AUTOSAR XML (schema 4-2-2)
package /AUTOSAR_Dem/SwComponentTypes
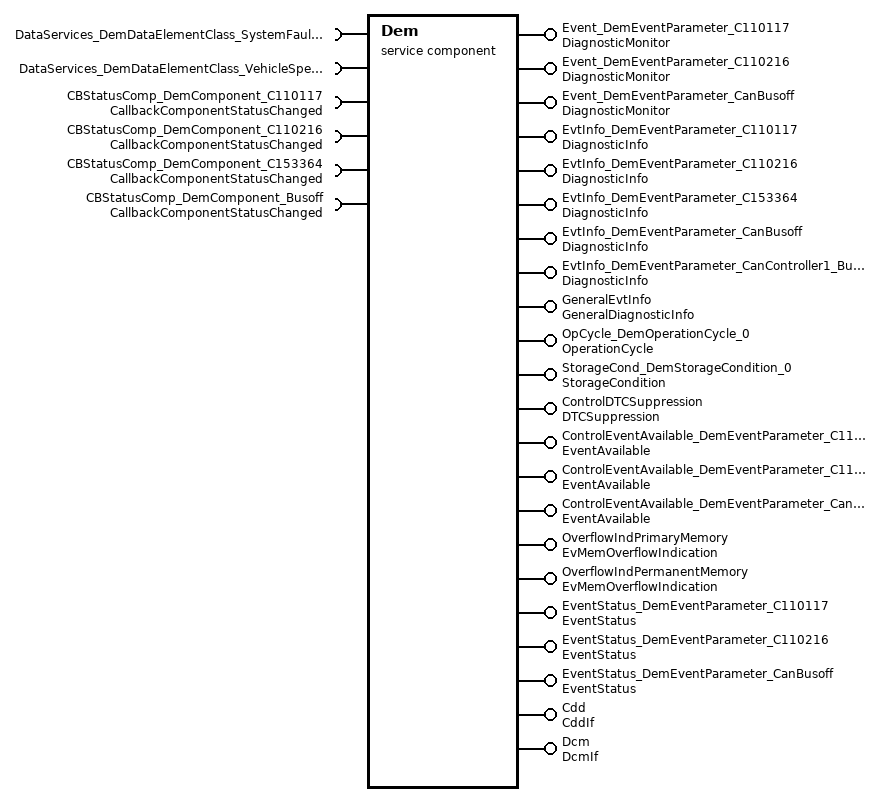
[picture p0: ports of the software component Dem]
  service sw component type Dem
    20 x provide port:
      Event_DemEventParameter_C110117: provided-interface=DiagnosticMonitor
      Event_DemEventParameter_C110216: provided-interface=DiagnosticMonitor
      Event_DemEventParameter_CanBusoff: provided-interface=DiagnosticMonitor
      EvtInfo_DemEventParameter_C110117: provided-interface=DiagnosticInfo
      EvtInfo_DemEventParameter_C110216: provided-interface=DiagnosticInfo
      EvtInfo_DemEventParameter_C153364: provided-interface=DiagnosticInfo
      EvtInfo_DemEventParameter_CanBusoff: provided-interface=DiagnosticInfo
      EvtInfo_DemEventParameter_CanController1_Busoff: provided-interface=DiagnosticInfo
      GeneralEvtInfo: provided-interface=GeneralDiagnosticInfo
      OpCycle_DemOperationCycle_0: provided-interface=OperationCycle
      StorageCond_DemStorageCondition_0: provided-interface=StorageCondition
      ControlDTCSuppression: provided-interface=DTCSuppression
      ControlEventAvailable_DemEventParameter_C110117: provided-interface=EventAvailable
      ControlEventAvailable_DemEventParameter_C110216: provided-interface=EventAvailable
      ControlEventAvailable_DemEventParameter_CanBusoff: provided-interface=EventAvailable
      OverflowIndPrimaryMemory: provided-interface=EvMemOverflowIndication
      OverflowIndPermanentMemory: provided-interface=EvMemOverflowIndication
      EventStatus_DemEventParameter_C110117: provided-interface=EventStatus
      EventStatus_DemEventParameter_C110216: provided-interface=EventStatus
      EventStatus_DemEventParameter_CanBusoff: provided-interface=EventStatus
    6 x require port:
      DataServices_DemDataElementClass_SystemFaultRank: required-interface=DataServices_DemDataElementClass_SystemFaultRank
      DataServices_DemDataElementClass_VehicleSpeed: required-interface=DataServices_DemDataElementClass_VehicleSpeed
      CBStatusComp_DemComponent_C110117: required-interface=CallbackComponentStatusChanged
      CBStatusComp_DemComponent_C110216: required-interface=CallbackComponentStatusChanged
      CBStatusComp_DemComponent_C153364: required-interface=CallbackComponentStatusChanged
      CBStatusComp_DemComponent_Busoff: required-interface=CallbackComponentStatusChanged
    provide port Cdd: provided-interface=CddIf
    provide port Dcm: provided-interface=DcmIf
    behavior IntBeh_Dem: included-data-type-set=data-type=[Dem_DTCFormatType, Dem_DTCOriginType, Dem_EventIdType, Dem_UdsStatusByteType, Dem_EventStatusType, Dem_IndicatorIdType, Dem_IndicatorStatusType, Dem_InitMonitorReasonType, Dem_MaxDataValueType, Dem_OperationCycleIdType, Dem_OperationCycleStateType, Dem_ReturnClearDTCType, Dem_DebouncingStateType, Dem_DebounceResetStatusType]
      94 x operation invoked event:
        Ev_SES_DemEventParameter_C110117: start-on-event=SetEventStatus, operation=Event_DemEventParameter_C110117.SetEventStatus
        Ev_RES_DemEventParameter_C110117: start-on-event=ResetEventStatus, operation=Event_DemEventParameter_C110117.ResetEventStatus
        Ev_CPFF_DemEventParameter_C110117: start-on-event=ClearPrestoredFreezeFrame, operation=Event_DemEventParameter_C110117.ClearPrestoredFreezeFrame
        Ev_PFF_DemEventParameter_C110117: start-on-event=PrestoreFreezeFrame, operation=Event_DemEventParameter_C110117.PrestoreFreezeFrame
        Ev_RDS_DemEventParameter_C110117: start-on-event=ResetEventDebounceStatus, operation=Event_DemEventParameter_C110117.ResetEventDebounceStatus
        Ev_SES_DemEventParameter_C110216: start-on-event=SetEventStatus, operation=Event_DemEventParameter_C110216.SetEventStatus
        Ev_RES_DemEventParameter_C110216: start-on-event=ResetEventStatus, operation=Event_DemEventParameter_C110216.ResetEventStatus
        Ev_CPFF_DemEventParameter_C110216: start-on-event=ClearPrestoredFreezeFrame, operation=Event_DemEventParameter_C110216.ClearPrestoredFreezeFrame
        Ev_PFF_DemEventParameter_C110216: start-on-event=PrestoreFreezeFrame, operation=Event_DemEventParameter_C110216.PrestoreFreezeFrame
        Ev_RDS_DemEventParameter_C110216: start-on-event=ResetEventDebounceStatus, operation=Event_DemEventParameter_C110216.ResetEventDebounceStatus
        Ev_SES_DemEventParameter_CanBusoff: start-on-event=SetEventStatus, operation=Event_DemEventParameter_CanBusoff.SetEventStatus
        Ev_RES_DemEventParameter_CanBusoff: start-on-event=ResetEventStatus, operation=Event_DemEventParameter_CanBusoff.ResetEventStatus
        Ev_CPFF_DemEventParameter_CanBusoff: start-on-event=ClearPrestoredFreezeFrame, operation=Event_DemEventParameter_CanBusoff.ClearPrestoredFreezeFrame
        Ev_PFF_DemEventParameter_CanBusoff: start-on-event=PrestoreFreezeFrame, operation=Event_DemEventParameter_CanBusoff.PrestoreFreezeFrame
        Ev_RDS_DemEventParameter_CanBusoff: start-on-event=ResetEventDebounceStatus, operation=Event_DemEventParameter_CanBusoff.ResetEventDebounceStatus
        Ev_GES_DemEventParameter_C110117: start-on-event=GetEventStatus, operation=EvtInfo_DemEventParameter_C110117.GetEventStatus
        Ev_GEF_DemEventParameter_C110117: start-on-event=GetEventFailed, operation=EvtInfo_DemEventParameter_C110117.GetEventFailed
        Ev_GET_DemEventParameter_C110117: start-on-event=GetEventTested, operation=EvtInfo_DemEventParameter_C110117.GetEventTested
        Ev_GDOE_DemEventParameter_C110117: start-on-event=GetDTCOfEvent, operation=EvtInfo_DemEventParameter_C110117.GetDTCOfEvent
        Ev_GETDOE_DemEventParameter_C110117: start-on-event=GetDebouncingOfEvent, operation=EvtInfo_DemEventParameter_C110117.GetDebouncingOfEvent
        Ev_GFDC_DemEventParameter_C110117: start-on-event=GetFaultDetectionCounter, operation=EvtInfo_DemEventParameter_C110117.GetFaultDetectionCounter
        Ev_GEED_DemEventParameter_C110117: start-on-event=GetEventExtendedDataRecord, operation=EvtInfo_DemEventParameter_C110117.GetEventExtendedDataRecord
        Ev_GEEDR_DemEventParameter_C110117: start-on-event=GetEventExtendedDataRecordEx, operation=EvtInfo_DemEventParameter_C110117.GetEventExtendedDataRecordEx
        Ev_GEFFD_DemEventParameter_C110117: start-on-event=GetEventFreezeFrameData, operation=EvtInfo_DemEventParameter_C110117.GetEventFreezeFrameData
        Ev_GEFFDE_DemEventParameter_C110117: start-on-event=GetEventFreezeFrameDataEx, operation=EvtInfo_DemEventParameter_C110117.GetEventFreezeFrameDataEx
        Ev_GES_DemEventParameter_C110216: start-on-event=GetEventStatus, operation=EvtInfo_DemEventParameter_C110216.GetEventStatus
        Ev_GEF_DemEventParameter_C110216: start-on-event=GetEventFailed, operation=EvtInfo_DemEventParameter_C110216.GetEventFailed
        Ev_GET_DemEventParameter_C110216: start-on-event=GetEventTested, operation=EvtInfo_DemEventParameter_C110216.GetEventTested
        Ev_GDOE_DemEventParameter_C110216: start-on-event=GetDTCOfEvent, operation=EvtInfo_DemEventParameter_C110216.GetDTCOfEvent
        Ev_GETDOE_DemEventParameter_C110216: start-on-event=GetDebouncingOfEvent, operation=EvtInfo_DemEventParameter_C110216.GetDebouncingOfEvent
        Ev_GFDC_DemEventParameter_C110216: start-on-event=GetFaultDetectionCounter, operation=EvtInfo_DemEventParameter_C110216.GetFaultDetectionCounter
        Ev_GEED_DemEventParameter_C110216: start-on-event=GetEventExtendedDataRecord, operation=EvtInfo_DemEventParameter_C110216.GetEventExtendedDataRecord
        Ev_GEEDR_DemEventParameter_C110216: start-on-event=GetEventExtendedDataRecordEx, operation=EvtInfo_DemEventParameter_C110216.GetEventExtendedDataRecordEx
        Ev_GEFFD_DemEventParameter_C110216: start-on-event=GetEventFreezeFrameData, operation=EvtInfo_DemEventParameter_C110216.GetEventFreezeFrameData
        Ev_GEFFDE_DemEventParameter_C110216: start-on-event=GetEventFreezeFrameDataEx, operation=EvtInfo_DemEventParameter_C110216.GetEventFreezeFrameDataEx
        Ev_GES_DemEventParameter_C153364: start-on-event=GetEventStatus, operation=EvtInfo_DemEventParameter_C153364.GetEventStatus
        Ev_GEF_DemEventParameter_C153364: start-on-event=GetEventFailed, operation=EvtInfo_DemEventParameter_C153364.GetEventFailed
        Ev_GET_DemEventParameter_C153364: start-on-event=GetEventTested, operation=EvtInfo_DemEventParameter_C153364.GetEventTested
        Ev_GDOE_DemEventParameter_C153364: start-on-event=GetDTCOfEvent, operation=EvtInfo_DemEventParameter_C153364.GetDTCOfEvent
        Ev_GETDOE_DemEventParameter_C153364: start-on-event=GetDebouncingOfEvent, operation=EvtInfo_DemEventParameter_C153364.GetDebouncingOfEvent
        Ev_GFDC_DemEventParameter_C153364: start-on-event=GetFaultDetectionCounter, operation=EvtInfo_DemEventParameter_C153364.GetFaultDetectionCounter
        Ev_GEED_DemEventParameter_C153364: start-on-event=GetEventExtendedDataRecord, operation=EvtInfo_DemEventParameter_C153364.GetEventExtendedDataRecord
        Ev_GEEDR_DemEventParameter_C153364: start-on-event=GetEventExtendedDataRecordEx, operation=EvtInfo_DemEventParameter_C153364.GetEventExtendedDataRecordEx
        Ev_GEFFD_DemEventParameter_C153364: start-on-event=GetEventFreezeFrameData, operation=EvtInfo_DemEventParameter_C153364.GetEventFreezeFrameData
        Ev_GEFFDE_DemEventParameter_C153364: start-on-event=GetEventFreezeFrameDataEx, operation=EvtInfo_DemEventParameter_C153364.GetEventFreezeFrameDataEx
        Ev_GES_DemEventParameter_CanBusoff: start-on-event=GetEventStatus, operation=EvtInfo_DemEventParameter_CanBusoff.GetEventStatus
        Ev_GEF_DemEventParameter_CanBusoff: start-on-event=GetEventFailed, operation=EvtInfo_DemEventParameter_CanBusoff.GetEventFailed
        Ev_GET_DemEventParameter_CanBusoff: start-on-event=GetEventTested, operation=EvtInfo_DemEventParameter_CanBusoff.GetEventTested
        Ev_GDOE_DemEventParameter_CanBusoff: start-on-event=GetDTCOfEvent, operation=EvtInfo_DemEventParameter_CanBusoff.GetDTCOfEvent
        Ev_GETDOE_DemEventParameter_CanBusoff: start-on-event=GetDebouncingOfEvent, operation=EvtInfo_DemEventParameter_CanBusoff.GetDebouncingOfEvent
        Ev_GFDC_DemEventParameter_CanBusoff: start-on-event=GetFaultDetectionCounter, operation=EvtInfo_DemEventParameter_CanBusoff.GetFaultDetectionCounter
        Ev_GEED_DemEventParameter_CanBusoff: start-on-event=GetEventExtendedDataRecord, operation=EvtInfo_DemEventParameter_CanBusoff.GetEventExtendedDataRecord
        Ev_GEEDR_DemEventParameter_CanBusoff: start-on-event=GetEventExtendedDataRecordEx, operation=EvtInfo_DemEventParameter_CanBusoff.GetEventExtendedDataRecordEx
        Ev_GEFFD_DemEventParameter_CanBusoff: start-on-event=GetEventFreezeFrameData, operation=EvtInfo_DemEventParameter_CanBusoff.GetEventFreezeFrameData
        Ev_GEFFDE_DemEventParameter_CanBusoff: start-on-event=GetEventFreezeFrameDataEx, operation=EvtInfo_DemEventParameter_CanBusoff.GetEventFreezeFrameDataEx
        Ev_GES_DemEventParameter_CanController1_Busoff: start-on-event=GetEventStatus, operation=EvtInfo_DemEventParameter_CanController1_Busoff.GetEventStatus
        Ev_GEF_DemEventParameter_CanController1_Busoff: start-on-event=GetEventFailed, operation=EvtInfo_DemEventParameter_CanController1_Busoff.GetEventFailed
        Ev_GET_DemEventParameter_CanController1_Busoff: start-on-event=GetEventTested, operation=EvtInfo_DemEventParameter_CanController1_Busoff.GetEventTested
        Ev_GDOE_DemEventParameter_CanController1_Busoff: start-on-event=GetDTCOfEvent, operation=EvtInfo_DemEventParameter_CanController1_Busoff.GetDTCOfEvent
        Ev_GETDOE_DemEventParameter_CanController1_Busoff: start-on-event=GetDebouncingOfEvent, operation=EvtInfo_DemEventParameter_CanController1_Busoff.GetDebouncingOfEvent
        Ev_GFDC_DemEventParameter_CanController1_Busoff: start-on-event=GetFaultDetectionCounter, operation=EvtInfo_DemEventParameter_CanController1_Busoff.GetFaultDetectionCounter
        Ev_GEED_DemEventParameter_CanController1_Busoff: start-on-event=GetEventExtendedDataRecord, operation=EvtInfo_DemEventParameter_CanController1_Busoff.GetEventExtendedDataRecord
        Ev_GEEDR_DemEventParameter_CanController1_Busoff: start-on-event=GetEventExtendedDataRecordEx, operation=EvtInfo_DemEventParameter_CanController1_Busoff.GetEventExtendedDataRecordEx
        Ev_GEFFD_DemEventParameter_CanController1_Busoff: start-on-event=GetEventFreezeFrameData, operation=EvtInfo_DemEventParameter_CanController1_Busoff.GetEventFreezeFrameData
        Ev_GEFFDE_DemEventParameter_CanController1_Busoff: start-on-event=GetEventFreezeFrameDataEx, operation=EvtInfo_DemEventParameter_CanController1_Busoff.GetEventFreezeFrameDataEx
        GDI_GDOE_GetDebouncingOfEvent: start-on-event=GetDebouncingOfEvent_GeneralEvtInfo, operation=GeneralEvtInfo.GetDebouncingOfEvent
        GDI_GES_GetEventStatus: start-on-event=Dem_GetEventStatus_GeneralEvtInfo, operation=GeneralEvtInfo.GetEventStatus
        GDI_GEF_GetEventFailed: start-on-event=Dem_GetEventFailed_GeneralEvtInfo, operation=GeneralEvtInfo.GetEventFailed
        GDI_GET_GetEventTested: start-on-event=Dem_GetEventTested_GeneralEvtInfo, operation=GeneralEvtInfo.GetEventTested
        GDI_GDE_GetDTCOfEvent: start-on-event=Dem_GetDTCOfEvent_GeneralEvtInfo, operation=GeneralEvtInfo.GetDTCOfEvent
        GDI_GFDC_GetFaultDetectionCounter: start-on-event=Dem_GetFaultDetectionCounter_GeneralEvtInfo, operation=GeneralEvtInfo.GetFaultDetectionCounter
        GDI_GEED_GetEventExtendedDataRecord: start-on-event=Dem_GetEventExtendedDataRecord_GeneralEvtInfo, operation=GeneralEvtInfo.GetEventExtendedDataRecord
        GDI_GEFFD_GetEventFreezeFrameData: start-on-event=Dem_GetEventFreezeFrameData_GeneralEvtInfo, operation=GeneralEvtInfo.GetEventFreezeFrameData
        GDI_GEED_GetEventExtendedDataRecordEx: start-on-event=Dem_GetEventExtendedDataRecordEx_GeneralEvtInfo, operation=GeneralEvtInfo.GetEventExtendedDataRecordEx
        GDI_GEFFD_GetEventFreezeFrameDataEx: start-on-event=Dem_GetEventFreezeFrameDataEx_GeneralEvtInfo, operation=GeneralEvtInfo.GetEventFreezeFrameDataEx
        OpCycle_OCS_DemOperationCycle_0: start-on-event=SetOperationCycleState, operation=OpCycle_DemOperationCycle_0.SetOperationCycleState
        OpCycle_GOCS_DemOperationCycle_0: start-on-event=GetOperationCycleState, operation=OpCycle_DemOperationCycle_0.GetOperationCycleState
        OpCycle_GCQ_DemOperationCycle_0: start-on-event=GetCycleQualified, operation=OpCycle_DemOperationCycle_0.GetCycleQualified
        OpCycle_SCQ_DemOperationCycle_0: start-on-event=SetCycleQualified, operation=OpCycle_DemOperationCycle_0.SetCycleQualified
        StorageCond_SSC_DemStorageCondition_0: start-on-event=SetStorageCondition, operation=StorageCond_DemStorageCondition_0.SetStorageCondition
        StorageCond_GSC_DemStorageCondition_0: start-on-event=GetStorageCondition, operation=StorageCond_DemStorageCondition_0.GetStorageCondition
        ControlDTCSuppression: start-on-event=SetDTCSuppression, operation=ControlDTCSuppression.SetDTCSuppression
        EvMemOverflow_GNOEE_OverflowIndPrimaryMemory: start-on-event=GetNumberOfEventMemoryEntries, operation=OverflowIndPrimaryMemory.GetNumberOfEventMemoryEntries
        EvMemOverflow_GEMO_OverflowIndPrimaryMemory: start-on-event=GetEventMemoryOverflow, operation=OverflowIndPrimaryMemory.GetEventMemoryOverflow
        EvMemOverflow_GEMO_OverflowIndPermanentMemory: start-on-event=GetEventMemoryOverflow, operation=OverflowIndPermanentMemory.GetEventMemoryOverflow
        EvMemOverflow_GNOEE_OverflowIndPermanentMemory: start-on-event=GetNumberOfEventMemoryEntries, operation=OverflowIndPermanentMemory.GetNumberOfEventMemoryEntries
        Ev_SetWIRStatus_DemEventParameter_C110117: start-on-event=SetWIRStatus, operation=EventStatus_DemEventParameter_C110117.SetWIRStatus
        Ev_SetWIRStatus_DemEventParameter_C110216: start-on-event=SetWIRStatus, operation=EventStatus_DemEventParameter_C110216.SetWIRStatus
        Ev_SetWIRStatus_DemEventParameter_CanBusoff: start-on-event=SetWIRStatus, operation=EventStatus_DemEventParameter_CanBusoff.SetWIRStatus
        Cdd: start-on-event=ClearDTC, operation=Cdd.ClearDTC
        Dcm: start-on-event=ClearDTC, operation=Dcm.ClearDTC
        EventAvailable_SetEventAvailable_DemEventParameter_C110117: start-on-event=SetEventAvailable, operation=ControlEventAvailable_DemEventParameter_C110117.SetEventAvailable
        EventAvailable_SetEventAvailable_DemEventParameter_C110216: start-on-event=SetEventAvailable, operation=ControlEventAvailable_DemEventParameter_C110216.SetEventAvailable
        EventAvailable_SetEventAvailable_DemEventParameter_CanBusoff: start-on-event=SetEventAvailable, operation=ControlEventAvailable_DemEventParameter_CanBusoff.SetEventAvailable
      port-api-options:
        {enable-take-address=true, indirect-api=false, port-defined-argument-value{value=EvtInfo_DemEventParameter_C110117:1, value-type=Dem_EventIdType}, port=EvtInfo_DemEventParameter_C110117}
        {enable-take-address=true, indirect-api=false, port-defined-argument-value{value=EvtInfo_DemEventParameter_C110216:2, value-type=Dem_EventIdType}, port=EvtInfo_DemEventParameter_C110216}
        {enable-take-address=true, indirect-api=false, port-defined-argument-value{value=EvtInfo_DemEventParameter_C153364:3, value-type=Dem_EventIdType}, port=EvtInfo_DemEventParameter_C153364}
        {enable-take-address=true, indirect-api=false, port-defined-argument-value{value=EvtInfo_DemEventParameter_CanBusoff:4, value-type=Dem_EventIdType}, port=EvtInfo_DemEventParameter_CanBusoff}
        {enable-take-address=true, indirect-api=false, port-defined-argument-value{value=EvtInfo_DemEventParameter_CanController1_Busoff:5, value-type=Dem_EventIdType}, port=EvtInfo_DemEventParameter_CanController1_Busoff}
        {enable-take-address=true, indirect-api=false, port-defined-argument-value{value=Event_DemEventParameter_C110117:1, value-type=Dem_EventIdType}, port=Event_DemEventParameter_C110117}
        {enable-take-address=true, indirect-api=false, port-defined-argument-value{value=EventStatus_DemEventParameter_C110117:1, value-type=Dem_EventIdType}, port=EventStatus_DemEventParameter_C110117}
        {enable-take-address=true, indirect-api=false, port-defined-argument-value{value=Event_DemEventParameter_C110216:2, value-type=Dem_EventIdType}, port=Event_DemEventParameter_C110216}
        {enable-take-address=true, indirect-api=false, port-defined-argument-value{value=EventStatus_DemEventParameter_C110216:2, value-type=Dem_EventIdType}, port=EventStatus_DemEventParameter_C110216}
        {enable-take-address=true, indirect-api=false, port-defined-argument-value{value=Event_DemEventParameter_CanBusoff:4, value-type=Dem_EventIdType}, port=Event_DemEventParameter_CanBusoff}
        {enable-take-address=true, indirect-api=false, port-defined-argument-value{value=EventStatus_DemEventParameter_CanBusoff:4, value-type=Dem_EventIdType}, port=EventStatus_DemEventParameter_CanBusoff}
        {enable-take-address=true, indirect-api=false, port-defined-argument-value{value=OpCycle_DemOperationCycle_0:0, value-type=Dem_OperationCycleIdType}, port=OpCycle_DemOperationCycle_0}
        {enable-take-address=true, indirect-api=false, port-defined-argument-value{value=StorageCond_DemStorageCondition_0:0, value-type=uint8}, port=StorageCond_DemStorageCondition_0}
        enable-take-address=true, indirect-api=false, port=ControlDTCSuppression
        enable-take-address=true, indirect-api=false, port=Cdd
        enable-take-address=true, indirect-api=false, port=Dcm
        {enable-take-address=true, indirect-api=false, port-defined-argument-value{value=OverflowIndPrimaryMemory:1, value-type=Dem_DTCOriginType}, port=OverflowIndPrimaryMemory}
        {enable-take-address=true, indirect-api=false, port-defined-argument-value{value=OverflowIndPermanentMemory:3, value-type=Dem_DTCOriginType}, port=OverflowIndPermanentMemory}
        enable-take-address=true, indirect-api=false, port=GeneralEvtInfo
        {enable-take-address=true, indirect-api=false, port-defined-argument-value{value=ControlEventAvailable_DemEventParameter_C110117:1, value-type=Dem_EventIdType}, port=ControlEventAvailable_DemEventParameter_C110117}
        {enable-take-address=true, indirect-api=false, port-defined-argument-value{value=ControlEventAvailable_DemEventParameter_C110216:2, value-type=Dem_EventIdType}, port=ControlEventAvailable_DemEventParameter_C110216}
        {enable-take-address=true, indirect-api=false, port-defined-argument-value{value=ControlEventAvailable_DemEventParameter_CanBusoff:4, value-type=Dem_EventIdType}, port=ControlEventAvailable_DemEventParameter_CanBusoff}
        enable-take-address=true, indirect-api=false, port=DataServices_DemDataElementClass_SystemFaultRank
        enable-take-address=true, indirect-api=false, port=DataServices_DemDataElementClass_VehicleSpeed
      40 x runnable:
        Dem_MainFunction
          6 x sync call, all with timeout=0.0:
            SSC_DataServices_DemDataElementClass_SystemFaultRank_ReadData: operation=DataServices_DemDataElementClass_SystemFaultRank.ReadData
            SSC_DataServices_DemDataElementClass_VehicleSpeed_ReadData: operation=DataServices_DemDataElementClass_VehicleSpeed.ReadData
            SSC_CBStatusComp_DemComponent_C110117: operation=CBStatusComp_DemComponent_C110117.ComponentStatusChanged
            SSC_CBStatusComp_DemComponent_C110216: operation=CBStatusComp_DemComponent_C110216.ComponentStatusChanged
            SSC_CBStatusComp_DemComponent_C153364: operation=CBStatusComp_DemComponent_C153364.ComponentStatusChanged
            SSC_CBStatusComp_DemComponent_Busoff: operation=CBStatusComp_DemComponent_Busoff.ComponentStatusChanged
        SetEventStatus: can-be-invoked-concurrently=true, symbol=Dem_SetEventStatus
        ResetEventStatus: can-be-invoked-concurrently=true, symbol=Dem_ResetEventStatus
        PrestoreFreezeFrame: can-be-invoked-concurrently=true, symbol=Dem_PrestoreFreezeFrame
        ClearPrestoredFreezeFrame: can-be-invoked-concurrently=true, symbol=Dem_ClearPrestoredFreezeFrame
        ResetEventDebounceStatus: can-be-invoked-concurrently=true, symbol=Dem_ResetEventDebounceStatus
        GetEventStatus: can-be-invoked-concurrently=true, symbol=Dem_GetEventStatus
        GetEventFailed: can-be-invoked-concurrently=true, symbol=Dem_GetEventFailed
        GetEventTested: can-be-invoked-concurrently=true, symbol=Dem_GetEventTested
        GetDTCOfEvent: can-be-invoked-concurrently=true, symbol=Dem_GetDTCOfEvent
        GetDebouncingOfEvent: can-be-invoked-concurrently=true, symbol=Dem_GetDebouncingOfEvent
        GetFaultDetectionCounter: can-be-invoked-concurrently=true, symbol=Dem_GetFaultDetectionCounter
        SetWIRStatus: can-be-invoked-concurrently=true, symbol=Dem_SetWIRStatus
        GetEventExtendedDataRecord: can-be-invoked-concurrently=true, symbol=Dem_GetEventExtendedDataRecordForRTE
        GetEventExtendedDataRecordEx: can-be-invoked-concurrently=true, symbol=Dem_GetEventExtendedDataRecordEx
        GetEventFreezeFrameData: can-be-invoked-concurrently=true, symbol=Dem_GetEventFreezeFrameDataForRTE
        GetEventFreezeFrameDataEx: can-be-invoked-concurrently=true, symbol=Dem_GetEventFreezeFrameDataEx
        SetOperationCycleState: can-be-invoked-concurrently=true, symbol=Dem_SetOperationCycleState
        GetOperationCycleState: can-be-invoked-concurrently=true, symbol=Dem_GetOperationCycleState
        GetCycleQualified: can-be-invoked-concurrently=true, symbol=Dem_GetCycleQualified
        SetCycleQualified: can-be-invoked-concurrently=true, symbol=Dem_SetCycleQualified
        SetEnableCondition: can-be-invoked-concurrently=true, symbol=Dem_SetEnableCondition
        SetStorageCondition: can-be-invoked-concurrently=true, symbol=Dem_SetStorageCondition
        GetStorageCondition: can-be-invoked-concurrently=true, symbol=Dem_GetStorageCondition
        GetIndicatorStatus: can-be-invoked-concurrently=true, symbol=Dem_GetIndicatorStatus
        SetDTCSuppression: symbol=Dem_SetDTCSuppression
        GetEventMemoryOverflow: can-be-invoked-concurrently=true, symbol=Dem_GetEventMemoryOverflow
        GetNumberOfEventMemoryEntries: can-be-invoked-concurrently=true, symbol=Dem_GetNumberOfEventMemoryEntries
        ClearDTC: symbol=Dem_ClearDTC
        Dem_GetEventStatus_GeneralEvtInfo: can-be-invoked-concurrently=true
        Dem_GetEventFailed_GeneralEvtInfo: can-be-invoked-concurrently=true
        Dem_GetEventTested_GeneralEvtInfo: can-be-invoked-concurrently=true
        Dem_GetDTCOfEvent_GeneralEvtInfo: can-be-invoked-concurrently=true
        Dem_GetFaultDetectionCounter_GeneralEvtInfo: can-be-invoked-concurrently=true
        Dem_GetEventExtendedDataRecord_GeneralEvtInfo: can-be-invoked-concurrently=true
        Dem_GetEventFreezeFrameData_GeneralEvtInfo: can-be-invoked-concurrently=true
        Dem_GetEventExtendedDataRecordEx_GeneralEvtInfo: can-be-invoked-concurrently=true
        Dem_GetEventFreezeFrameDataEx_GeneralEvtInfo: can-be-invoked-concurrently=true
        GetDebouncingOfEvent_GeneralEvtInfo: can-be-invoked-concurrently=true, symbol=Dem_GetDebouncingOfEvent_GeneralEvtInfo
        SetEventAvailable: can-be-invoked-concurrently=true, symbol=Dem_SetEventAvailable
package /AUTOSAR_Dem/PortInterfaces
  16 x client server interface, all with is-service=true:
    DiagnosticMonitor
      5 x operation, all with possible-error=[DiagnosticMonitor/E_OK, DiagnosticMonitor/E_NOT_OK]:
        SetEventStatus
          arg EventStatus: type=Dem_EventStatusType, direction=IN
        ResetEventStatus
        PrestoreFreezeFrame
        ClearPrestoredFreezeFrame
        ResetEventDebounceStatus
          arg DebounceResetStatus: type=Dem_DebounceResetStatusType, direction=IN
      error E_OK: error-code=0
      error E_NOT_OK: error-code=1
    DiagnosticInfo
      10 x operation:
        GetEventStatus: possible-error=[DiagnosticInfo/E_OK, DiagnosticInfo/E_NOT_OK]
          arg EventStatusByte: type=Dem_UdsStatusByteType, direction=OUT
        GetEventFailed: possible-error=[DiagnosticInfo/E_OK, DiagnosticInfo/E_NOT_OK]
          arg EventFailed: type=boolean, direction=OUT
        GetEventTested: possible-error=[DiagnosticInfo/E_OK, DiagnosticInfo/E_NOT_OK]
          arg EventTested: type=boolean, direction=OUT
        GetDTCOfEvent: possible-error=[DiagnosticInfo/E_OK, DiagnosticInfo/E_NOT_OK, DiagnosticInfo/DEM_E_NO_DTC_AVAILABLE]
          arg DTCFormat: type=Dem_DTCFormatType, direction=IN
          arg DTCOfEvent: type=uint32, direction=OUT
        GetDebouncingOfEvent: possible-error=[DiagnosticInfo/E_OK, DiagnosticInfo/E_NOT_OK]
          arg DebouncingState: type=Dem_DebouncingStateType, direction=OUT
        GetFaultDetectionCounter: possible-error=[DiagnosticInfo/E_OK, DiagnosticInfo/E_NOT_OK, DiagnosticInfo/DEM_E_NO_FDC_AVAILABLE]
          arg FaultDetectionCounter: type=sint8, direction=OUT
        GetEventExtendedDataRecord: possible-error=[DiagnosticInfo/E_OK, DiagnosticInfo/E_NOT_OK]
          arg RecordNumber: type=uint8, direction=IN
          arg DestBuffer: type=Dem_MaxDataValueType, direction=OUT
        GetEventExtendedDataRecordEx: possible-error=[DiagnosticInfo/E_OK, DiagnosticInfo/E_NOT_OK]
          arg RecordNumber: type=uint8, direction=IN
          arg DestBuffer: type=Dem_MaxDataValueType, direction=OUT
          arg Bufsize: type=uint16, direction=INOUT
        GetEventFreezeFrameData: possible-error=[DiagnosticInfo/E_OK, DiagnosticInfo/E_NOT_OK]
          4 x arg:
            RecordNumber: type=uint8, direction=IN
            ReportTotalRecord: type=boolean, direction=IN
            DataId: type=uint16, direction=IN
            DestBuffer: type=Dem_MaxDataValueType, direction=OUT
        GetEventFreezeFrameDataEx: possible-error=[DiagnosticInfo/E_OK, DiagnosticInfo/E_NOT_OK]
          4 x arg:
            RecordNumber: type=uint8, direction=IN
            DataId: type=uint16, direction=IN
            DestBuffer: type=Dem_MaxDataValueType, direction=OUT
            BufSize: type=uint16, direction=INOUT
      4 x error:
        E_OK: error-code=0
        E_NOT_OK: error-code=1
        DEM_E_NO_DTC_AVAILABLE: error-code=2
        DEM_E_NO_FDC_AVAILABLE: error-code=3
    GeneralDiagnosticInfo
      10 x operation:
        GetEventStatus: possible-error=[GeneralDiagnosticInfo/E_OK, GeneralDiagnosticInfo/E_NOT_OK]
          arg EventId: type=Dem_EventIdType, direction=IN
          arg EventStatusByte: type=Dem_UdsStatusByteType, direction=OUT
        GetEventFailed: possible-error=[GeneralDiagnosticInfo/E_OK, GeneralDiagnosticInfo/E_NOT_OK]
          arg EventId: type=Dem_EventIdType, direction=IN
          arg EventFailed: type=boolean, direction=OUT
        GetEventTested: possible-error=[GeneralDiagnosticInfo/E_OK, GeneralDiagnosticInfo/E_NOT_OK]
          arg EventId: type=Dem_EventIdType, direction=IN
          arg EventTested: type=boolean, direction=OUT
        GetDTCOfEvent: possible-error=[GeneralDiagnosticInfo/E_OK, GeneralDiagnosticInfo/E_NOT_OK, GeneralDiagnosticInfo/DEM_E_NO_DTC_AVAILABLE]
          arg EventId: type=Dem_EventIdType, direction=IN
          arg DTCFormat: type=Dem_DTCFormatType, direction=IN
          arg DTCOfEvent: type=uint32, direction=OUT
        GetDebouncingOfEvent: possible-error=[GeneralDiagnosticInfo/E_OK, GeneralDiagnosticInfo/E_NOT_OK]
          arg EventId: type=Dem_EventIdType, direction=IN
          arg DebouncingState: type=Dem_DebouncingStateType, direction=OUT
        GetFaultDetectionCounter: possible-error=[GeneralDiagnosticInfo/E_OK, GeneralDiagnosticInfo/E_NOT_OK, GeneralDiagnosticInfo/DEM_E_NO_FDC_AVAILABLE]
          arg EventId: type=Dem_EventIdType, direction=IN
          arg FaultDetectionCounter: type=sint8, direction=OUT
        GetEventExtendedDataRecord: possible-error=[GeneralDiagnosticInfo/E_OK, GeneralDiagnosticInfo/E_NOT_OK]
          arg EventId: type=Dem_EventIdType, direction=IN
          arg RecordNumber: type=uint8, direction=IN
          arg DestBuffer: type=Dem_MaxDataValueType, direction=OUT
        GetEventFreezeFrameData: possible-error=[GeneralDiagnosticInfo/E_OK, GeneralDiagnosticInfo/E_NOT_OK]
          5 x arg:
            EventId: type=Dem_EventIdType, direction=IN
            RecordNumber: type=uint8, direction=IN
            ReportTotalRecord: type=boolean, direction=IN
            DataId: type=uint16, direction=IN
            DestBuffer: type=Dem_MaxDataValueType, direction=OUT
        GetEventExtendedDataRecordEx: possible-error=[GeneralDiagnosticInfo/E_OK, GeneralDiagnosticInfo/E_NOT_OK]
          4 x arg:
            EventId: type=Dem_EventIdType, direction=IN
            RecordNumber: type=uint8, direction=IN
            DestBuffer: type=Dem_MaxDataValueType, direction=OUT
            Bufsize: type=uint16, direction=INOUT
        GetEventFreezeFrameDataEx: possible-error=[GeneralDiagnosticInfo/E_OK, GeneralDiagnosticInfo/E_NOT_OK]
          5 x arg:
            EventId: type=Dem_EventIdType, direction=IN
            RecordNumber: type=uint8, direction=IN
            DataId: type=uint16, direction=IN
            DestBuffer: type=Dem_MaxDataValueType, direction=OUT
            BufSize: type=uint16, direction=INOUT
      4 x error:
        E_OK: error-code=0
        E_NOT_OK: error-code=1
        DEM_E_NO_DTC_AVAILABLE: error-code=2
        DEM_E_NO_FDC_AVAILABLE: error-code=3
    OperationCycle
      4 x operation, all with possible-error=[OperationCycle/E_OK, OperationCycle/E_NOT_OK]:
        SetOperationCycleState
          arg CycleState: type=Dem_OperationCycleStateType, direction=IN
        GetOperationCycleState
          arg CycleState: type=Dem_OperationCycleStateType, direction=OUT
        GetCycleQualified
          arg CycleState: type=boolean, direction=OUT
        SetCycleQualified
      error E_OK: error-code=0
      error E_NOT_OK: error-code=1
    EventAvailable
      operation SetEventAvailable: possible-error=[EventAvailable/E_OK, EventAvailable/E_NOT_OK]
        arg AvailableStatus: type=boolean, direction=IN
      error E_OK: error-code=0
      error E_NOT_OK: error-code=1
    EnableCondition
      operation SetEnableCondition: possible-error=[EnableCondition/E_OK, EnableCondition/E_NOT_OK]
        arg ConditionFulfilled: type=boolean, direction=IN
      error E_OK: error-code=0
      error E_NOT_OK: error-code=1
    StorageCondition
      operation SetStorageCondition: possible-error=[StorageCondition/E_OK, StorageCondition/E_NOT_OK]
        arg ConditionFulfilled: type=boolean, direction=IN
      operation GetStorageCondition: possible-error=[StorageCondition/E_OK, StorageCondition/E_NOT_OK]
        arg ConditionFulfilled: type=boolean, direction=OUT
      error E_OK: error-code=0
      error E_NOT_OK: error-code=1
    IndicatorStatus
      operation GetIndicatorStatus: possible-error=[IndicatorStatus/E_OK, IndicatorStatus/E_NOT_OK]
        arg IndicatorStatus: type=Dem_IndicatorStatusType, direction=OUT
      error E_OK: error-code=0
      error E_NOT_OK: error-code=1
    DTCSuppression
      operation SetDTCSuppression: possible-error=[DTCSuppression/E_OK, DTCSuppression/E_NOT_OK]
        arg DTC: type=uint32, direction=IN
        arg DTCFormat: type=Dem_DTCFormatType, direction=IN
        arg SuppressionStatus: type=boolean, direction=IN
      error E_OK: error-code=0
      error E_NOT_OK: error-code=1
    EvMemOverflowIndication
      operation GetEventMemoryOverflow: possible-error=[EvMemOverflowIndication/E_OK, EvMemOverflowIndication/E_NOT_OK]
        arg OverflowIndication: type=boolean, direction=OUT
      operation GetNumberOfEventMemoryEntries: possible-error=[EvMemOverflowIndication/E_OK, EvMemOverflowIndication/E_NOT_OK]
        arg NumberOfEventMemoryEntries: type=uint8, direction=OUT
      error E_OK: error-code=0
      error E_NOT_OK: error-code=1
    DataServices_DemDataElementClass_SystemFaultRank
      operation ReadData: possible-error=[DataServices_DemDataElementClass_SystemFaultRank/E_OK, DataServices_DemDataElementClass_SystemFaultRank/E_NOT_OK]
        arg Data: type=DemDataElememtDataSize_DemDataElementClass_SystemFaultRank, direction=OUT
      error E_OK: error-code=0
      error E_NOT_OK: error-code=1
    DataServices_DemDataElementClass_VehicleSpeed
      operation ReadData: possible-error=[DataServices_DemDataElementClass_VehicleSpeed/E_OK, DataServices_DemDataElementClass_VehicleSpeed/E_NOT_OK]
        arg Data: type=DemDataElememtDataSize_DemDataElementClass_VehicleSpeed, direction=OUT
      error E_OK: error-code=0
      error E_NOT_OK: error-code=1
    CallbackComponentStatusChanged
      operation ComponentStatusChanged
        arg ComponentFailedStatus: type=boolean, direction=IN
    EventStatus
      operation SetWIRStatus: possible-error=[EventStatus/E_OK, EventStatus/E_NOT_OK]
        arg WIRStatus: type=boolean, direction=IN
      error E_OK: error-code=0
      error E_NOT_OK: error-code=1
    CddIf
      operation ClearDTC: possible-error=[CddIf/DEM_CLEAR_FAILED, CddIf/DEM_CLEAR_PENDING, CddIf/DEM_CLEAR_WRONG_DTC, CddIf/DEM_CLEAR_WRONG_DTCORIGIN, CddIf/DEM_CLEAR_MEMORY_ERROR]
        arg DTC: type=uint32, direction=IN
        arg DTCFormat: type=Dem_DTCFormatType, direction=IN
        arg DTCOrigin: type=Dem_DTCOriginType, direction=IN
      5 x error:
        DEM_CLEAR_WRONG_DTC: error-code=1
        DEM_CLEAR_WRONG_DTCORIGIN: error-code=2
        DEM_CLEAR_FAILED: error-code=3
        DEM_CLEAR_PENDING: error-code=4
        DEM_CLEAR_MEMORY_ERROR: error-code=6
    DcmIf
      operation ClearDTC: possible-error=[DcmIf/E_OK, DcmIf/DEM_CLEAR_FAILED, DcmIf/DEM_CLEAR_PENDING, DcmIf/DEM_CLEAR_WRONG_DTC, DcmIf/DEM_CLEAR_WRONG_DTCORIGIN, DEM_CLEAR_BUSY, DcmIf/DEM_CLEAR_MEMORY_ERROR]
        arg DTC: type=uint32, direction=IN
        arg DTCFormat: type=Dem_DTCFormatType, direction=IN
        arg DTCOrigin: type=Dem_DTCOriginType, direction=IN
      7 x error:
        E_OK: error-code=0
        DEM_CLEAR_WRONG_DTC: error-code=1
        DEM_CLEAR_WRONG_DTCORIGIN: error-code=2
        DEM_CLEAR_FAILED: error-code=3
        DEM_CLEAR_PENDING: error-code=4
        DEM_CLEAR_BUSY: error-code=5
        DEM_CLEAR_MEMORY_ERROR: error-code=6
package /AUTOSAR_Dem/SwcImplementations
  swc implementation Impl_Dem: programming-language=C, sw-version=4.0.0, swc-bsw-mapping=SwcBswMappings, vendor-id=6, behavior=IntBeh_Dem
    code-descriptors:
      code CodeDescr_Dem: artifact-descriptors=autosar-engineering-object={short-label=Code_0, category=SWSRC}
package /AUTOSAR_Dem/ImplementationDataTypes
  16 x impl type:
    Dem_EventStatusType: compu {1=DEM_EVENT_STATUS_FAILED, 4=DEM_EVENT_STATUS_FDC_THRESHOLD_REACHED, 0=DEM_EVENT_STATUS_PASSED, 3=DEM_EVENT_STATUS_PREFAILED, 2=DEM_EVENT_STATUS_PREPASSED}, implementation-data-type=uint8
    Dem_EventIdType: implementation-data-type=uint16
    Dem_UdsStatusByteType: compu {0x01=DEM_UDS_STATUS_TF, 0x02=DEM_UDS_STATUS_TFTOC, 0x04=DEM_UDS_STATUS_PDTC, 0x08=DEM_UDS_STATUS_CDTC, 0x10=DEM_UDS_STATUS_TNCSLC, 0x20=DEM_UDS_STATUS_TFSLC, 0x40=DEM_UDS_STATUS_TNCTOC, 0x80=DEM_UDS_STATUS_WIR}, implementation-data-type=uint8
    Dem_OperationCycleStateType: compu {0x01=DEM_CYCLE_STATE_END, 0x00=DEM_CYCLE_STATE_START}, implementation-data-type=uint8
    Dem_OperationCycleIdType: implementation-data-type=uint8
    Dem_MaxDataValueType: category=ARRAY, type-emitter=RTE
      element uint8: array-size=2, array-size-semantics=FIXED-SIZE, implementation-data-type=uint8
    Dem_IndicatorIdType: implementation-data-type=uint8
    Dem_IndicatorStatusType: compu {0x00=DEM_INDICATOR_OFF, 0x01=DEM_INDICATOR_CONTINUOUS, 0x02=DEM_INDICATOR_BLINKING, 0x03=DEM_INDICATOR_BLINK_CONT, 0x04=DEM_INDICATOR_SLOW_FLASH, 0x05=DEM_INDICATOR_FAST_FLASH}, implementation-data-type=uint8
    Dem_DTCOriginType: compu {0x01=DEM_DTC_ORIGIN_PRIMARY_MEMORY, 0x02=DEM_DTC_ORIGIN_MIRROR_MEMORY, 0x03=DEM_DTC_ORIGIN_PERMANENT_MEMORY, 0x04=DEM_DTC_ORIGIN_SECONDARY_MEMORY}, implementation-data-type=uint8
    Dem_InitMonitorReasonType: compu {0x01=DEM_INIT_MONITOR_CLEAR, 0x02=DEM_INIT_MONITOR_RESTART, 0x03=DEM_INIT_MONITOR_REENABLED, 0x04=DEM_INIT_MONITOR_STORAGE_REENABLED}, implementation-data-type=uint8
    Dem_DTCFormatType: compu {0=DEM_DTC_FORMAT_OBD, 1=DEM_DTC_FORMAT_UDS, 2=DEM_DTC_FORMAT_J1939}, implementation-data-type=uint8
    Dem_ReturnClearDTCType: compu {0=DEM_CLEAR_OK, 1=DEM_CLEAR_WRONG_DTC, 2=DEM_CLEAR_WRONG_DTCORIGIN, 3=DEM_CLEAR_FAILED, 4=DEM_CLEAR_PENDING, 5=DEM_CLEAR_BUSY, 6=DEM_CLEAR_MEMORY_ERROR}, implementation-data-type=uint8
    Dem_DebouncingStateType: compu {0x01=DEM_TEMPORARILY_DEFECTIVE, 0x02=DEM_FINALLY_DEFECTIVE, 0x04=DEM_TEMPORARILY_HEALED, 0x08=DEM_TEST_COMPLETE, 0x10=DEM_DTR_UPDATE}, implementation-data-type=uint8
    Dem_DebounceResetStatusType: compu {0x00=DEM_DEBOUNCE_STATUS_FREEZE, 0x01=DEM_DEBOUNCE_STATUS_RESET}, implementation-data-type=uint8
    DemDataElememtDataSize_DemDataElementClass_SystemFaultRank: category=ARRAY
      element DemDataElememtDataSize_DemDataElementClass_SystemFaultRank: array-size=1, array-size-semantics=FIXED-SIZE, implementation-data-type=uint8
    DemDataElememtDataSize_DemDataElementClass_VehicleSpeed: category=ARRAY
      element DemDataElememtDataSize_DemDataElementClass_VehicleSpeed: array-size=2, array-size-semantics=FIXED-SIZE, implementation-data-type=uint8
package /AUTOSAR_Dem/SwcBswMappings
  swc bsw mapping SwcBswMappings: bsw-behavior=IB_Dem, swc-bsw-runnable-mapping{bsw-entity=BSWSE_DemMainFunction, swc-runnable=Dem_MainFunction}, swc-behavior=IntBeh_Dem
